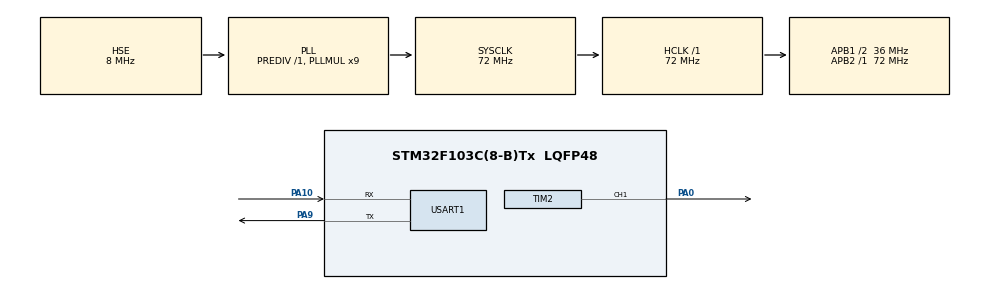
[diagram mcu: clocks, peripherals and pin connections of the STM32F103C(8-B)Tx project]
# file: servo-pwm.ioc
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Mcu.Family=STM32F1
RCC.PLLSourceVirtual=RCC_PLLSOURCE_HSE
Dma.USART1_TX.1.Instance=DMA1_Channel4
FREERTOS.Tasks01=defaultTask,24,128,StartDefaultTask,Default,NULL,Dynamic,NULL,NULL
NVIC.DMA1_Channel5_IRQn=true\:5\:0\:false\:false\:true\:true\:false\:true
PD1-OSC_OUT.Mode=HSE-External-Oscillator
Dma.USART1_RX.0.PeriphDataAlignment=DMA_PDATAALIGN_BYTE
PA10.Mode=Asynchronous
Dma.USART1_TX.1.MemInc=DMA_MINC_ENABLE
PD0-OSC_IN.Signal=RCC_OSC_IN
RCC.APB1CLKDivider=RCC_HCLK_DIV2
RCC.SYSCLKSource=RCC_SYSCLKSOURCE_PLLCLK
ProjectManager.StackSize=0x400
PA0-WKUP.Signal=S_TIM2_CH1_ETR
VP_FREERTOS_VS_CMSIS_V2.Mode=CMSIS_V2
PD1-OSC_OUT.Signal=RCC_OSC_OUT
PA13.Signal=SYS_JTMS-SWDIO
PA9.Mode=Asynchronous
ProjectManager.TargetToolchain=Makefile
Dma.USART1_RX.0.Direction=DMA_PERIPH_TO_MEMORY
RCC.HCLKFreq_Value=72000000
RCC.APB2TimFreq_Value=72000000
PA9.Signal=USART1_TX
RCC.USBFreq_Value=72000000
RCC.AHBFreq_Value=72000000
Dma.USART1_RX.0.PeriphInc=DMA_PINC_DISABLE
Dma.USART1_RX.0.Priority=DMA_PRIORITY_LOW
PD0-OSC_IN.Mode=HSE-External-Oscillator
PA0-WKUP.GPIO_Speed=GPIO_SPEED_FREQ_HIGH
Dma.USART1_TX.1.MemDataAlignment=DMA_MDATAALIGN_BYTE
board=custom
RCC.PLLMUL=RCC_PLL_MUL9
RCC.APB2Freq_Value=72000000
VP_TIM2_VS_ClockSourceINT.Mode=Internal
PA14.Mode=Serial_Wire
NVIC.TIM2_IRQn=true\:5\:0\:false\:false\:true\:true\:true\:true
Dma.USART1_RX.0.MemDataAlignment=DMA_MDATAALIGN_BYTE
TIM2.Channel-PWM\ Generation1\ CH1=TIM_CHANNEL_1
TIM2.Period=19999
Dma.USART1_RX.0.MemInc=DMA_MINC_ENABLE
PA13.Mode=Serial_Wire
Mcu.Name=STM32F103C(8-B)Tx
Dma.USART1_TX.1.PeriphDataAlignment=DMA_PDATAALIGN_BYTE
RCC.SYSCLKFreq_VALUE=72000000
Mcu.Package=LQFP48
TIM2.Prescaler=71
NVIC.TimeBase=TIM4_IRQn
Dma.USART1_TX.1.Mode=DMA_NORMAL
USART1.VirtualMode=VM_ASYNC
SH.S_TIM2_CH1_ETR.0=TIM2_CH1,PWM Generation1 CH1
NVIC.TimeBaseIP=TIM4
PA10.Signal=USART1_RX
PA14.Signal=SYS_JTCK-SWCLK
ProjectManager.HeapSize=0x200
Dma.USART1_TX.1.PeriphInc=DMA_PINC_DISABLE
VP_SYS_VS_tim4.Mode=TIM4
NVIC.PriorityGroup=NVIC_PRIORITYGROUP_4
Dma.Request1=USART1_TX
RCC.APB1TimFreq_Value=72000000
Dma.USART1_RX.0.Mode=DMA_NORMAL
Dma.USART1_TX.1.Priority=DMA_PRIORITY_LOW
NVIC.DMA1_Channel4_IRQn=true\:5\:0\:false\:false\:true\:true\:false\:true
NVIC.USART1_IRQn=true\:5\:0\:false\:false\:true\:true\:true\:true
NVIC.TIM4_IRQn=true\:0\:0\:false\:false\:true\:false\:false\:true
Dma.Request0=USART1_RX
RCC.APB1Freq_Value=36000000
Dma.USART1_RX.0.Instance=DMA1_Channel5
NVIC.RCC_IRQn=true\:5\:0\:false\:false\:true\:true\:true\:false
Dma.USART1_TX.1.Direction=DMA_MEMORY_TO_PERIPH

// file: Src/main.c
/* USER CODE BEGIN Header */
/**
  ******************************************************************************
  * @file           : main.c
  * @brief          : Main program body
  ******************************************************************************
  * @attention
  *
  * <h2><center>&copy; Copyright (c) 2020 STMicroelectronics.
  * All rights reserved.</center></h2>
  *
  * This software component is licensed by ST under Ultimate Liberty license
  * SLA0044, the "License"; You may not use this file except in compliance with
  * the License. You may obtain a copy of the License at:
  *                             www.st.com/SLA0044
  *
  ******************************************************************************
  */
/* USER CODE END Header */

#include "main.h"
#include "cmsis_os.h"

/* USER CODE BEGIN Includes */
#include <stm32f103xb.h>
#include <stdarg.h>
#include <stdio.h>
#include <string.h>
/* USER CODE END Includes */

TIM_HandleTypeDef htim2;

UART_HandleTypeDef huart1;
DMA_HandleTypeDef hdma_usart1_rx;
DMA_HandleTypeDef hdma_usart1_tx;

/* Definitions for defaultTask */
osThreadId_t defaultTaskHandle;
const osThreadAttr_t defaultTask_attributes = {
  .name = "defaultTask",
  .priority = (osPriority_t) osPriorityNormal,
  .stack_size = 128 * 4
};
/* USER CODE BEGIN PV */
static char tx_buff[] = "hello world!\r\n";
static char rx_buff[10] = {0};
static void Println(char *fmt, ...){
    char buff[128] = {0};
    va_list argptr;
    va_start(argptr, fmt);
    vsnprintf(buff, 126, fmt, argptr);
    va_end(argptr);
    int idx = strlen(buff);
    buff[idx++] = '\r';
    buff[idx++] = '\n';
    buff[idx] = 0;
    HAL_UART_Transmit_DMA(&huart1, (uint8_t *)buff, strlen(buff));
}

static void Print(char *fmt, ...){
    char buff[128] = {0};
    va_list argptr;
    va_start(argptr, fmt);
    vsnprintf(buff, 127, fmt, argptr);
    va_end(argptr);
    HAL_UART_Transmit_DMA(&huart1, (uint8_t *)buff, strlen(buff));
}

/* USER CODE END PV */

void SystemClock_Config(void);
static void MX_GPIO_Init(void);
static void MX_DMA_Init(void);
static void MX_TIM2_Init(void);
static void MX_USART1_UART_Init(void);
void StartDefaultTask(void *argument);

int main(void)
{

  /* MCU Configuration--------------------------------------------------------*/

  /* Reset of all peripherals, Initializes the Flash interface and the Systick. */
  HAL_Init();

  /* Configure the system clock */
  SystemClock_Config();

  /* Initialize all configured peripherals */
  MX_GPIO_Init();
  MX_DMA_Init();
  MX_TIM2_Init();
  MX_USART1_UART_Init();
  /* USER CODE BEGIN 2 */
  HAL_UART_Transmit_DMA(&huart1, (uint8_t *)tx_buff, strlen(tx_buff));
  HAL_UART_Receive_DMA(&huart1, (uint8_t *)rx_buff, 10);
  HAL_TIM_PWM_Start(&htim2, TIM_CHANNEL_1);
  /* USER CODE END 2 */

  /* Init scheduler */
  osKernelInitialize();

  /* Create the thread(s) */
  /* creation of defaultTask */
  defaultTaskHandle = osThreadNew(StartDefaultTask, NULL, &defaultTask_attributes);

  /* Start scheduler */
  osKernelStart();

  /* We should never get here as control is now taken by the scheduler */
  /* Infinite loop */
  while (1)
  {

  }
}

void SystemClock_Config(void)
{
  RCC_OscInitTypeDef RCC_OscInitStruct = {0};
  RCC_ClkInitTypeDef RCC_ClkInitStruct = {0};

  /** Initializes the CPU, AHB and APB busses clocks
  */
  RCC_OscInitStruct.OscillatorType = RCC_OSCILLATORTYPE_HSE;
  RCC_OscInitStruct.HSEState = RCC_HSE_ON;
  RCC_OscInitStruct.HSEPredivValue = RCC_HSE_PREDIV_DIV1;
  RCC_OscInitStruct.HSIState = RCC_HSI_ON;
  RCC_OscInitStruct.PLL.PLLState = RCC_PLL_ON;
  RCC_OscInitStruct.PLL.PLLSource = RCC_PLLSOURCE_HSE;
  RCC_OscInitStruct.PLL.PLLMUL = RCC_PLL_MUL9;
  if (HAL_RCC_OscConfig(&RCC_OscInitStruct) != HAL_OK)
  {
    Error_Handler();
  }
  /** Initializes the CPU, AHB and APB busses clocks
  */
  RCC_ClkInitStruct.ClockType = RCC_CLOCKTYPE_HCLK|RCC_CLOCKTYPE_SYSCLK
                              |RCC_CLOCKTYPE_PCLK1|RCC_CLOCKTYPE_PCLK2;
  RCC_ClkInitStruct.SYSCLKSource = RCC_SYSCLKSOURCE_PLLCLK;
  RCC_ClkInitStruct.AHBCLKDivider = RCC_SYSCLK_DIV1;
  RCC_ClkInitStruct.APB1CLKDivider = RCC_HCLK_DIV2;
  RCC_ClkInitStruct.APB2CLKDivider = RCC_HCLK_DIV1;

  if (HAL_RCC_ClockConfig(&RCC_ClkInitStruct, FLASH_LATENCY_2) != HAL_OK)
  {
    Error_Handler();
  }
}

static void MX_TIM2_Init(void)
{

  TIM_ClockConfigTypeDef sClockSourceConfig = {0};
  TIM_MasterConfigTypeDef sMasterConfig = {0};
  TIM_OC_InitTypeDef sConfigOC = {0};

  htim2.Instance = TIM2;
  htim2.Init.Prescaler = 71;
  htim2.Init.CounterMode = TIM_COUNTERMODE_UP;
  htim2.Init.Period = 19999;
  htim2.Init.ClockDivision = TIM_CLOCKDIVISION_DIV1;
  htim2.Init.AutoReloadPreload = TIM_AUTORELOAD_PRELOAD_DISABLE;
  if (HAL_TIM_Base_Init(&htim2) != HAL_OK)
  {
    Error_Handler();
  }
  sClockSourceConfig.ClockSource = TIM_CLOCKSOURCE_INTERNAL;
  if (HAL_TIM_ConfigClockSource(&htim2, &sClockSourceConfig) != HAL_OK)
  {
    Error_Handler();
  }
  if (HAL_TIM_PWM_Init(&htim2) != HAL_OK)
  {
    Error_Handler();
  }
  sMasterConfig.MasterOutputTrigger = TIM_TRGO_RESET;
  sMasterConfig.MasterSlaveMode = TIM_MASTERSLAVEMODE_DISABLE;
  if (HAL_TIMEx_MasterConfigSynchronization(&htim2, &sMasterConfig) != HAL_OK)
  {
    Error_Handler();
  }
  sConfigOC.OCMode = TIM_OCMODE_PWM1;
  sConfigOC.Pulse = 0;
  sConfigOC.OCPolarity = TIM_OCPOLARITY_HIGH;
  sConfigOC.OCFastMode = TIM_OCFAST_DISABLE;
  if (HAL_TIM_PWM_ConfigChannel(&htim2, &sConfigOC, TIM_CHANNEL_1) != HAL_OK)
  {
    Error_Handler();
  }
  HAL_TIM_MspPostInit(&htim2);

}

static void MX_USART1_UART_Init(void)
{

  huart1.Instance = USART1;
  huart1.Init.BaudRate = 115200;
  huart1.Init.WordLength = UART_WORDLENGTH_8B;
  huart1.Init.StopBits = UART_STOPBITS_1;
  huart1.Init.Parity = UART_PARITY_NONE;
  huart1.Init.Mode = UART_MODE_TX_RX;
  huart1.Init.HwFlowCtl = UART_HWCONTROL_NONE;
  huart1.Init.OverSampling = UART_OVERSAMPLING_16;
  if (HAL_UART_Init(&huart1) != HAL_OK)
  {
    Error_Handler();
  }

}

static void MX_DMA_Init(void)
{

  /* DMA controller clock enable */
  __HAL_RCC_DMA1_CLK_ENABLE();

  /* DMA interrupt init */
  /* DMA1_Channel4_IRQn interrupt configuration */
  HAL_NVIC_SetPriority(DMA1_Channel4_IRQn, 5, 0);
  HAL_NVIC_EnableIRQ(DMA1_Channel4_IRQn);
  /* DMA1_Channel5_IRQn interrupt configuration */
  HAL_NVIC_SetPriority(DMA1_Channel5_IRQn, 5, 0);
  HAL_NVIC_EnableIRQ(DMA1_Channel5_IRQn);

}

static void MX_GPIO_Init(void)
{
  /* GPIO Ports Clock Enable */
  __HAL_RCC_GPIOD_CLK_ENABLE();
  __HAL_RCC_GPIOA_CLK_ENABLE();
  GPIO_InitTypeDef GpioInitSt;
  GpioInitSt.Pin = GPIO_PIN_0;
  GpioInitSt.Mode = GPIO_MODE_AF_PP;
  GpioInitSt.Speed = GPIO_SPEED_FREQ_HIGH;
  HAL_GPIO_Init(GPIOA, &GpioInitSt);

}

/* USER CODE BEGIN 4 */

HAL_UART_RxCpltCallback(UART_HandleTypeDef *h){

}

HAL_UART_TxHalfCpltCallback(UART_HandleTypeDef *h){

}

HAL_UART_ErrorCallback(UART_HandleTypeDef *h){

}

/* USER CODE END 4 */

void StartDefaultTask(void *argument)
{
  /* USER CODE BEGIN 5 */
  /* Infinite loop */
  unsigned int ccr1 = 0;
  unsigned int x = 0;
  //unsigned int steps[] = {1000,1500, 2000};
  for(unsigned int i = 0;;i+=30)
  {
      // 0.5ms : 20ms == x : 1000 =>x = 25
      // 2.5ms : 20ms == x: 1000 => x = 125

      // 1ms :20 ms = x:1000 => x = 50
      // 2ms : 20ms = x: 1000 = > x = 100

      ccr1 = (i % 1001) + 1000;
      htim2.Instance->CCR1 = ccr1;
      //x = (unsigned int)(ccr1/50.0 * 100);
      //Println("%d,%d.%dms", i, x/100, x%100);
      osDelay(100/portTICK_PERIOD_MS);
  }
  /* USER CODE END 5 */
}

 /**
  * @brief  Period elapsed callback in non blocking mode
  * @note   This function is called  when TIM4 interrupt took place, inside
  * HAL_TIM_IRQHandler(). It makes a direct call to HAL_IncTick() to increment
  * a global variable "uwTick" used as application time base.
  * @param  htim : TIM handle
  * @retval None
  */
void HAL_TIM_PeriodElapsedCallback(TIM_HandleTypeDef *htim)
{
  if (htim->Instance == TIM4) {
    HAL_IncTick();
  }
}

void Error_Handler(void)
{
}

/************************ (C) COPYRIGHT STMicroelectronics *****END OF FILE****/
